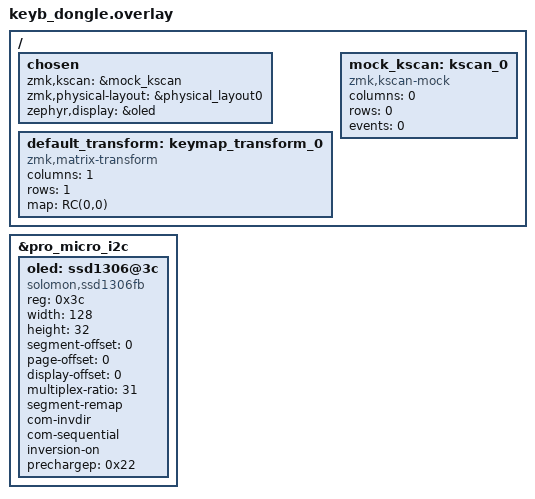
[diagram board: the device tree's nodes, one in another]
#include <dt-bindings/zmk/matrix_transform.h>

#include "keyb-layouts.dtsi"

/ {
    chosen {
        zmk,kscan = &mock_kscan;
        zmk,physical-layout = &physical_layout0;
        zephyr,display = &oled;
    };

    default_transform: keymap_transform_0 {
        compatible = "zmk,matrix-transform";
        columns = <1>;
        rows = <1>;
        map = < RC(0,0) >;
    };

    mock_kscan: kscan_0 {
        compatible = "zmk,kscan-mock";
        columns = <0>;
        rows = <0>;
        events = <0>;
    };
};

&pro_micro_i2c {
    status = "okay";

    oled: ssd1306@3c {
        compatible = "solomon,ssd1306fb";
        reg = <0x3c>;
        width = <128>;
        height = <32>;
        segment-offset = <0>;
        page-offset = <0>;
        display-offset = <0>;
        multiplex-ratio = <31>;
        segment-remap;
        com-invdir;
        com-sequential;
        inversion-on;
        prechargep = <0x22>;
    };
};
